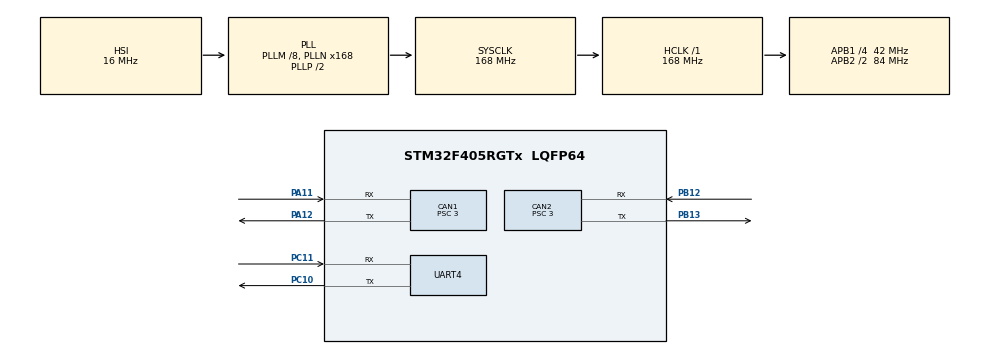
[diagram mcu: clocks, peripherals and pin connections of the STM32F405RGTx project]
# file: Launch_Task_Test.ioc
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CAN1.BS1=CAN_BS1_10TQ
CAN1.BS2=CAN_BS2_3TQ
CAN1.CalculateBaudRate=1000000
CAN1.CalculateTimeBit=1000
CAN1.CalculateTimeQuantum=71.42857142857143
CAN1.Prescaler=3
CAN1.SJW=CAN_SJW_2TQ
CAN2.BS1=CAN_BS1_10TQ
CAN2.BS2=CAN_BS2_3TQ
CAN2.CalculateBaudRate=1000000
CAN2.CalculateTimeBit=1000
CAN2.CalculateTimeQuantum=71.42857142857143
CAN2.Prescaler=3
CAN2.SJW=CAN_SJW_2TQ
Dma.Request0=UART4_RX
Dma.Request1=UART4_TX
Dma.UART4_RX.0.Direction=DMA_PERIPH_TO_MEMORY
Dma.UART4_RX.0.FIFOMode=DMA_FIFOMODE_DISABLE
Dma.UART4_RX.0.Instance=DMA1_Stream2
Dma.UART4_RX.0.MemDataAlignment=DMA_MDATAALIGN_BYTE
Dma.UART4_RX.0.MemInc=DMA_MINC_ENABLE
Dma.UART4_RX.0.Mode=DMA_NORMAL
Dma.UART4_RX.0.PeriphDataAlignment=DMA_PDATAALIGN_BYTE
Dma.UART4_RX.0.PeriphInc=DMA_PINC_DISABLE
Dma.UART4_RX.0.Priority=DMA_PRIORITY_LOW
Dma.UART4_TX.1.Direction=DMA_MEMORY_TO_PERIPH
Dma.UART4_TX.1.FIFOMode=DMA_FIFOMODE_DISABLE
Dma.UART4_TX.1.Instance=DMA1_Stream4
Dma.UART4_TX.1.MemDataAlignment=DMA_MDATAALIGN_BYTE
Dma.UART4_TX.1.MemInc=DMA_MINC_ENABLE
Dma.UART4_TX.1.Mode=DMA_NORMAL
Dma.UART4_TX.1.PeriphDataAlignment=DMA_PDATAALIGN_BYTE
Dma.UART4_TX.1.PeriphInc=DMA_PINC_DISABLE
Dma.UART4_TX.1.Priority=DMA_PRIORITY_LOW
FREERTOS.Queues01=transport,16,uint16_t,0,Dynamic,NULL,NULL
FREERTOS.Tasks01=defaultTask,24,128,StartDefaultTask,Default,NULL,Dynamic,NULL,NULL;launch_task,8,256,launch,As weak,NULL,Dynamic,NULL,NULL;vofa_print,8,128,vofa,As weak,NULL,Dynamic,NULL,NULL
Mcu.Family=STM32F4
Mcu.Name=STM32F405RGTx
Mcu.Package=LQFP64
NVIC.DMA1_Stream2_IRQn=true\:5\:0\:false\:false\:true\:true\:false\:true\:true
NVIC.DMA1_Stream4_IRQn=true\:5\:0\:false\:false\:true\:true\:false\:true\:true
NVIC.PriorityGroup=NVIC_PRIORITYGROUP_4
NVIC.TIM1_UP_TIM10_IRQn=true\:15\:0\:false\:false\:true\:false\:false\:true\:true
NVIC.TimeBase=TIM1_UP_TIM10_IRQn
NVIC.TimeBaseIP=TIM1
NVIC.UART4_IRQn=true\:5\:0\:false\:false\:true\:true\:false\:true\:true
PA11.Mode=CAN_Activate
PA11.Signal=CAN1_RX
PA12.Mode=CAN_Activate
PA12.Signal=CAN1_TX
PA13.Mode=Serial_Wire
PA13.Signal=SYS_JTMS-SWDIO
PA14.Mode=Serial_Wire
PA14.Signal=SYS_JTCK-SWCLK
PB12.Mode=CAN_Activate
PB12.Signal=CAN2_RX
PB13.Mode=CAN_Activate
PB13.Signal=CAN2_TX
PC10.Mode=Asynchronous
PC10.Signal=UART4_TX
PC11.Mode=Asynchronous
PC11.Signal=UART4_RX
PH0-OSC_IN.Mode=HSE-External-Clock-Source
PH0-OSC_IN.Signal=RCC_OSC_IN
PH1-OSC_OUT.Mode=HSE-External-Clock-Source
PH1-OSC_OUT.Signal=RCC_OSC_OUT
ProjectManager.HeapSize=0x200
ProjectManager.StackSize=0x400
ProjectManager.TargetToolchain=MDK-ARM V5.32
RCC.48MHZClocksFreq_Value=84000000
RCC.AHBFreq_Value=168000000
RCC.APB1CLKDivider=RCC_HCLK_DIV4
RCC.APB1Freq_Value=42000000
RCC.APB1TimFreq_Value=84000000
RCC.APB2CLKDivider=RCC_HCLK_DIV2
RCC.APB2Freq_Value=84000000
RCC.APB2TimFreq_Value=168000000
RCC.CortexFreq_Value=168000000
RCC.HCLKFreq_Value=168000000
RCC.HSE_VALUE=25000000
RCC.HSI_VALUE=16000000
RCC.LSE_VALUE=32768
RCC.PLLM=8
RCC.PLLN=168
RCC.SYSCLKFreq_VALUE=168000000
RCC.SYSCLKSource=RCC_SYSCLKSOURCE_PLLCLK
RCC.VCOOutputFreq_Value=336000000
UART4.VirtualMode=Asynchronous
VP_FREERTOS_VS_CMSIS_V2.Mode=CMSIS_V2
VP_SYS_VS_tim1.Mode=TIM1
board=custom

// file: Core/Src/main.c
/* USER CODE BEGIN Header */
/**
  ******************************************************************************
  * @file           : main.c
  * @brief          : Main program body
  ******************************************************************************
  * @attention
  *
  * Copyright (c) 2026 STMicroelectronics.
  * All rights reserved.
  *
  * This software is licensed under terms that can be found in the LICENSE file
  * in the root directory of this software component.
  * If no LICENSE file comes with this software, it is provided AS-IS.
  *
  ******************************************************************************
  */
/* USER CODE END Header */
#include "main.h"
#include "cmsis_os.h"

/* USER CODE BEGIN Includes */
#include "launch_controller.h"

/* USER CODE END Includes */

CAN_HandleTypeDef hcan1;
CAN_HandleTypeDef hcan2;

UART_HandleTypeDef huart4;
DMA_HandleTypeDef hdma_uart4_rx;
DMA_HandleTypeDef hdma_uart4_tx;

/* Definitions for defaultTask */
osThreadId_t defaultTaskHandle;
const osThreadAttr_t defaultTask_attributes = {
  .name = "defaultTask",
  .stack_size = 128 * 4,
  .priority = (osPriority_t) osPriorityNormal,
};
/* Definitions for launch_task */
osThreadId_t launch_taskHandle;
const osThreadAttr_t launch_task_attributes = {
  .name = "launch_task",
  .stack_size = 256 * 4,
  .priority = (osPriority_t) osPriorityLow,
};
/* Definitions for vofa_print */
osThreadId_t vofa_printHandle;
const osThreadAttr_t vofa_print_attributes = {
  .name = "vofa_print",
  .stack_size = 128 * 4,
  .priority = (osPriority_t) osPriorityLow,
};
/* Definitions for transport */
osMessageQueueId_t transportHandle;
const osMessageQueueAttr_t transport_attributes = {
  .name = "transport"
};

void SystemClock_Config(void);
static void MX_GPIO_Init(void);
static void MX_DMA_Init(void);
static void MX_UART4_Init(void);
static void MX_CAN1_Init(void);
static void MX_CAN2_Init(void);
void StartDefaultTask(void *argument);
void launch(void *argument);
void vofa(void *argument);

int main(void)
{

  /* MCU Configuration--------------------------------------------------------*/

  /* Reset of all peripherals, Initializes the Flash interface and the Systick. */
  HAL_Init();

  /* Configure the system clock */
  SystemClock_Config();

  /* Initialize all configured peripherals */
  MX_GPIO_Init();
  MX_DMA_Init();
  MX_UART4_Init();
  MX_CAN1_Init();
  MX_CAN2_Init();
  /* USER CODE BEGIN 2 */
  /* UART4 is both the command port and VOFA telemetry port. */
  LaunchController_Init(&hcan1, &hcan2, &huart4);
  HAL_NVIC_SetPriority(CAN1_RX0_IRQn, 5, 0);
  HAL_NVIC_EnableIRQ(CAN1_RX0_IRQn);
  HAL_NVIC_SetPriority(CAN2_RX0_IRQn, 5, 0);
  HAL_NVIC_EnableIRQ(CAN2_RX0_IRQn);

  /* USER CODE END 2 */

  /* Init scheduler */
  osKernelInitialize();

  /* Create the queue(s) */
  /* creation of transport */
  transportHandle = osMessageQueueNew (16, sizeof(uint16_t), &transport_attributes);

  /* Create the thread(s) */
  /* creation of defaultTask */
  defaultTaskHandle = osThreadNew(StartDefaultTask, NULL, &defaultTask_attributes);

  /* creation of launch_task */
  launch_taskHandle = osThreadNew(launch, NULL, &launch_task_attributes);

  /* creation of vofa_print */
  vofa_printHandle = osThreadNew(vofa, NULL, &vofa_print_attributes);

  /* Start scheduler */
  osKernelStart();

  /* We should never get here as control is now taken by the scheduler */

  /* Infinite loop */
  while (1)
  {

  }
}

void SystemClock_Config(void)
{
  RCC_OscInitTypeDef RCC_OscInitStruct = {0};
  RCC_ClkInitTypeDef RCC_ClkInitStruct = {0};

  /** Configure the main internal regulator output voltage
  */
  __HAL_RCC_PWR_CLK_ENABLE();
  __HAL_PWR_VOLTAGESCALING_CONFIG(PWR_REGULATOR_VOLTAGE_SCALE1);

  /** Initializes the RCC Oscillators according to the specified parameters
  * in the RCC_OscInitTypeDef structure.
  */
  RCC_OscInitStruct.OscillatorType = RCC_OSCILLATORTYPE_HSI;
  RCC_OscInitStruct.HSIState = RCC_HSI_ON;
  RCC_OscInitStruct.HSICalibrationValue = RCC_HSICALIBRATION_DEFAULT;
  RCC_OscInitStruct.PLL.PLLState = RCC_PLL_ON;
  RCC_OscInitStruct.PLL.PLLSource = RCC_PLLSOURCE_HSI;
  RCC_OscInitStruct.PLL.PLLM = 8;
  RCC_OscInitStruct.PLL.PLLN = 168;
  RCC_OscInitStruct.PLL.PLLP = RCC_PLLP_DIV2;
  RCC_OscInitStruct.PLL.PLLQ = 4;
  if (HAL_RCC_OscConfig(&RCC_OscInitStruct) != HAL_OK)
  {
    Error_Handler();
  }

  /** Initializes the CPU, AHB and APB buses clocks
  */
  RCC_ClkInitStruct.ClockType = RCC_CLOCKTYPE_HCLK|RCC_CLOCKTYPE_SYSCLK
                              |RCC_CLOCKTYPE_PCLK1|RCC_CLOCKTYPE_PCLK2;
  RCC_ClkInitStruct.SYSCLKSource = RCC_SYSCLKSOURCE_PLLCLK;
  RCC_ClkInitStruct.AHBCLKDivider = RCC_SYSCLK_DIV1;
  RCC_ClkInitStruct.APB1CLKDivider = RCC_HCLK_DIV4;
  RCC_ClkInitStruct.APB2CLKDivider = RCC_HCLK_DIV2;

  if (HAL_RCC_ClockConfig(&RCC_ClkInitStruct, FLASH_LATENCY_5) != HAL_OK)
  {
    Error_Handler();
  }
}

static void MX_CAN1_Init(void)
{

  hcan1.Instance = CAN1;
  hcan1.Init.Prescaler = 3;
  hcan1.Init.Mode = CAN_MODE_NORMAL;
  hcan1.Init.SyncJumpWidth = CAN_SJW_2TQ;
  hcan1.Init.TimeSeg1 = CAN_BS1_10TQ;
  hcan1.Init.TimeSeg2 = CAN_BS2_3TQ;
  hcan1.Init.TimeTriggeredMode = DISABLE;
  hcan1.Init.AutoBusOff = DISABLE;
  hcan1.Init.AutoWakeUp = DISABLE;
  hcan1.Init.AutoRetransmission = DISABLE;
  hcan1.Init.ReceiveFifoLocked = DISABLE;
  hcan1.Init.TransmitFifoPriority = DISABLE;
  if (HAL_CAN_Init(&hcan1) != HAL_OK)
  {
    Error_Handler();
  }

}

static void MX_CAN2_Init(void)
{

  hcan2.Instance = CAN2;
  hcan2.Init.Prescaler = 3;
  hcan2.Init.Mode = CAN_MODE_NORMAL;
  hcan2.Init.SyncJumpWidth = CAN_SJW_2TQ;
  hcan2.Init.TimeSeg1 = CAN_BS1_10TQ;
  hcan2.Init.TimeSeg2 = CAN_BS2_3TQ;
  hcan2.Init.TimeTriggeredMode = DISABLE;
  hcan2.Init.AutoBusOff = DISABLE;
  hcan2.Init.AutoWakeUp = DISABLE;
  hcan2.Init.AutoRetransmission = DISABLE;
  hcan2.Init.ReceiveFifoLocked = DISABLE;
  hcan2.Init.TransmitFifoPriority = DISABLE;
  if (HAL_CAN_Init(&hcan2) != HAL_OK)
  {
    Error_Handler();
  }

}

static void MX_UART4_Init(void)
{

  huart4.Instance = UART4;
  huart4.Init.BaudRate = 115200;
  huart4.Init.WordLength = UART_WORDLENGTH_8B;
  huart4.Init.StopBits = UART_STOPBITS_1;
  huart4.Init.Parity = UART_PARITY_NONE;
  huart4.Init.Mode = UART_MODE_TX_RX;
  huart4.Init.HwFlowCtl = UART_HWCONTROL_NONE;
  huart4.Init.OverSampling = UART_OVERSAMPLING_16;
  if (HAL_UART_Init(&huart4) != HAL_OK)
  {
    Error_Handler();
  }

}

static void MX_DMA_Init(void)
{

  /* DMA controller clock enable */
  __HAL_RCC_DMA1_CLK_ENABLE();

  /* DMA interrupt init */
  /* DMA1_Stream2_IRQn interrupt configuration */
  HAL_NVIC_SetPriority(DMA1_Stream2_IRQn, 5, 0);
  HAL_NVIC_EnableIRQ(DMA1_Stream2_IRQn);
  /* DMA1_Stream4_IRQn interrupt configuration */
  HAL_NVIC_SetPriority(DMA1_Stream4_IRQn, 5, 0);
  HAL_NVIC_EnableIRQ(DMA1_Stream4_IRQn);
  /* UART4 全局中断用于释放 DMA 发送完成状态，并支持空闲接收。 */
  HAL_NVIC_SetPriority(UART4_IRQn, 5, 0);
  HAL_NVIC_EnableIRQ(UART4_IRQn);

}

static void MX_GPIO_Init(void)
{

  /* GPIO Ports Clock Enable */
  __HAL_RCC_GPIOH_CLK_ENABLE();
  __HAL_RCC_GPIOA_CLK_ENABLE();
  __HAL_RCC_GPIOB_CLK_ENABLE();
  __HAL_RCC_GPIOC_CLK_ENABLE();

}

void StartDefaultTask(void *argument)
{
  for(;;)
  {
    osDelay(1);
  }
}

__weak void launch(void *argument)
{
  for(;;)
  {
    osDelay(1);
  }
}

__weak void vofa(void *argument)
{
  for(;;)
  {
    osDelay(1);
  }
}

void HAL_TIM_PeriodElapsedCallback(TIM_HandleTypeDef *htim)
{
  if (htim->Instance == TIM1)
  {
    HAL_IncTick();
  }
}

void Error_Handler(void)
{
  __disable_irq();
  while (1)
  {
  }
}
